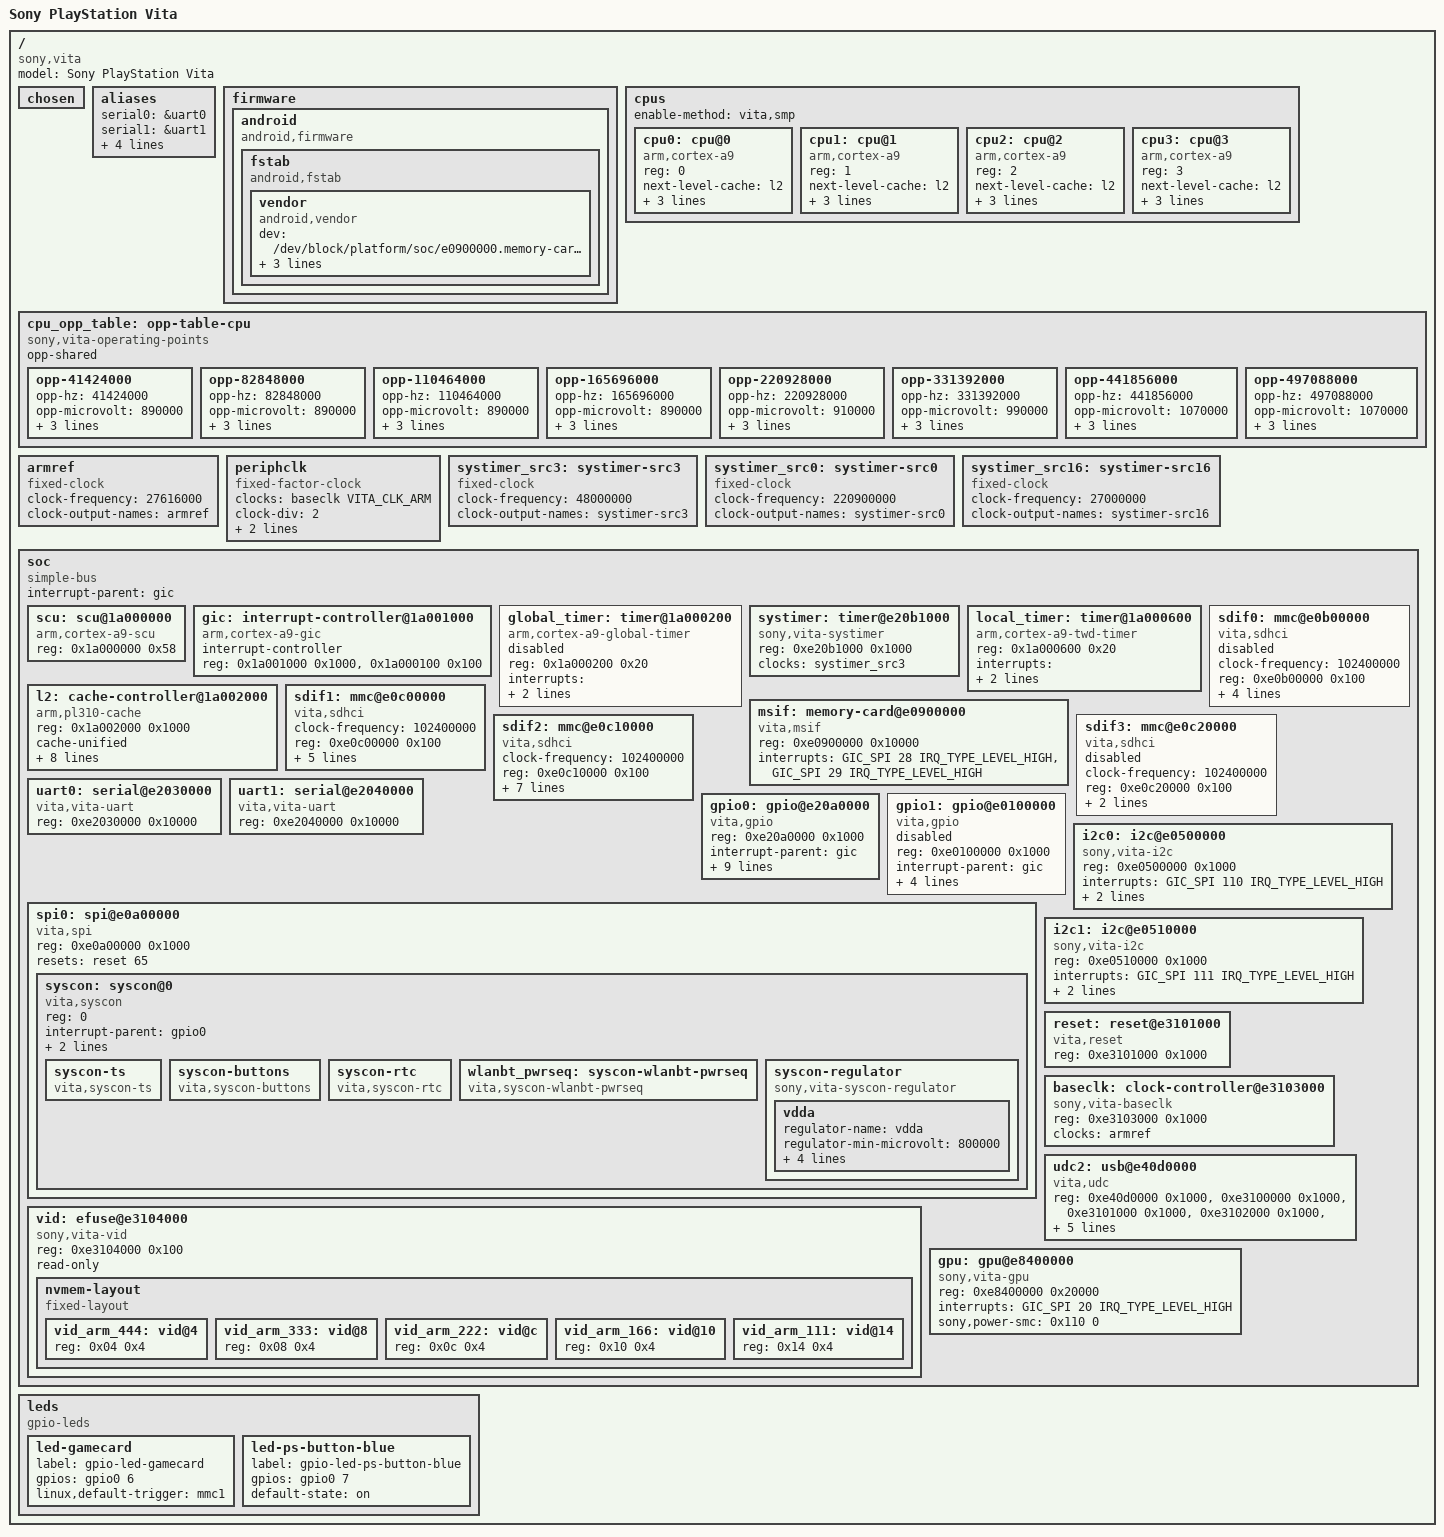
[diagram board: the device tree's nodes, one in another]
// SPDX-License-Identifier: GPL-2.0
/*
 * Base Device Tree Source for the PlayStation Vita (CXD5315GG SoC)
 *
 * Sources of the hardware values:
 *  [HW]   measured on a DevKit by a bare-metal test payload;
 *  [WIKI] the wiki.henkaku.xyz pages;
 *  [RE]   the Vita OS 3.65 modules, reverse engineered.
 * Interrupt numbers in the wiki's SceKernelIntrMgr table are GIC interrupt
 * IDs; GIC_SPI n below is ID - 32.
 */

#include <dt-bindings/clock/sony,vita-baseclk.h>
#include <dt-bindings/gpio/gpio.h>
#include <dt-bindings/interrupt-controller/arm-gic.h>
#include <dt-bindings/interrupt-controller/irq.h>

/ {
	model = "Sony PlayStation Vita";
	compatible = "sony,vita", "vita,vita";

	#address-cells = <1>;
	#size-cells = <1>;

	chosen {
		#address-cells = <1>;
		#size-cells = <1>;
		ranges;
	};

	aliases {
		serial0 = &uart0;
		serial1 = &uart1;
		/* Fixed MMC numbering: mmc0 is always the eMMC, mmc1 the game card slot */
		mmc0 = &sdif0;
		mmc1 = &sdif1;
		mmc2 = &sdif2;
		mmc3 = &sdif3;
	};

	/*
	 * Android's first-stage mount. The boot loader maps ux0:data/android/emmc.img
	 * to the GPT disk vitaemmc (see msif below); system is the root file
	 * system (root=PARTLABEL=system), vendor is mounted from here before
	 * SELinux loads its policy.
	 */
	firmware {
		android {
			compatible = "android,firmware";

			fstab {
				compatible = "android,fstab";

				vendor {
					compatible = "android,vendor";
					dev = "/dev/block/platform/soc/e0900000.memory-card/by-name/vendor";
					type = "ext4";
					mnt_flags = "ro,barrier=1";
					fsmgr_flags = "wait";
				};
			};
		};
	};

	cpus {
		#address-cells = <1>;
		#size-cells = <0>;
		/* Secondaries are parked by the loader at 0x1F007F00 + 4 * cpu */
		enable-method = "vita,smp";

		/* 4x Cortex-A9 r2p10 (MIDR 0x412FC09A) [WIKI CPU] */
		cpu0: cpu@0 {
			device_type = "cpu";
			compatible = "arm,cortex-a9";
			reg = <0>;
			next-level-cache = <&l2>;
			clocks = <&baseclk VITA_CLK_ARM>;
			cpu-supply = <&vdda>;
			operating-points-v2 = <&cpu_opp_table>;
		};

		cpu1: cpu@1 {
			device_type = "cpu";
			compatible = "arm,cortex-a9";
			reg = <1>;
			next-level-cache = <&l2>;
			clocks = <&baseclk VITA_CLK_ARM>;
			cpu-supply = <&vdda>;
			operating-points-v2 = <&cpu_opp_table>;
		};

		cpu2: cpu@2 {
			device_type = "cpu";
			compatible = "arm,cortex-a9";
			reg = <2>;
			next-level-cache = <&l2>;
			clocks = <&baseclk VITA_CLK_ARM>;
			cpu-supply = <&vdda>;
			operating-points-v2 = <&cpu_opp_table>;
		};

		cpu3: cpu@3 {
			device_type = "cpu";
			compatible = "arm,cortex-a9";
			reg = <3>;
			next-level-cache = <&l2>;
			clocks = <&baseclk VITA_CLK_ARM>;
			cpu-supply = <&vdda>;
			operating-points-v2 = <&cpu_opp_table>;
		};
	};

	/*
	 * The ARM clock's operating points: the selectors whose L2 clock is the
	 * core clock, the ones ScePower uses and the boot loader's 500 MHz
	 * (drivers/clk/clk-vita.c), at 27.616 MHz times 1.5, 3, 4, 6, 8, 12, 16
	 * and 18. Each OPP names the ScePervasiveVid cell ScePower takes for
	 * its level (power.skprx 3.65 0x810098e0), 500 MHz the one for 444 MHz
	 * as the boot loader does; the driver sets the voltage from it. The
	 * opp-microvolt values are those of the wiki's example chip.
	 * clock-latency-ns covers the Syscon voltage command, an estimate.
	 */
	cpu_opp_table: opp-table-cpu {
		compatible = "sony,vita-operating-points";
		opp-shared;

		opp-41424000 {
			opp-hz = /bits/ 64 <41424000>;
			opp-microvolt = <890000>;
			clock-latency-ns = <1000000>;
			nvmem-cells = <&vid_arm_111>;
			nvmem-cell-names = "vid";
		};

		opp-82848000 {
			opp-hz = /bits/ 64 <82848000>;
			opp-microvolt = <890000>;
			clock-latency-ns = <1000000>;
			nvmem-cells = <&vid_arm_111>;
			nvmem-cell-names = "vid";
		};

		opp-110464000 {
			opp-hz = /bits/ 64 <110464000>;
			opp-microvolt = <890000>;
			clock-latency-ns = <1000000>;
			nvmem-cells = <&vid_arm_111>;
			nvmem-cell-names = "vid";
		};

		opp-165696000 {
			opp-hz = /bits/ 64 <165696000>;
			opp-microvolt = <890000>;
			clock-latency-ns = <1000000>;
			nvmem-cells = <&vid_arm_166>;
			nvmem-cell-names = "vid";
		};

		opp-220928000 {
			opp-hz = /bits/ 64 <220928000>;
			opp-microvolt = <910000>;
			clock-latency-ns = <1000000>;
			nvmem-cells = <&vid_arm_222>;
			nvmem-cell-names = "vid";
		};

		opp-331392000 {
			opp-hz = /bits/ 64 <331392000>;
			opp-microvolt = <990000>;
			clock-latency-ns = <1000000>;
			nvmem-cells = <&vid_arm_333>;
			nvmem-cell-names = "vid";
		};

		opp-441856000 {
			opp-hz = /bits/ 64 <441856000>;
			opp-microvolt = <1070000>;
			clock-latency-ns = <1000000>;
			nvmem-cells = <&vid_arm_444>;
			nvmem-cell-names = "vid";
		};

		opp-497088000 {
			opp-hz = /bits/ 64 <497088000>;
			opp-microvolt = <1070000>;
			clock-latency-ns = <1000000>;
			nvmem-cells = <&vid_arm_444>;
			nvmem-cell-names = "vid";
		};
	};

	/* The memory node is per model: 512 MiB retail, 1 GiB DevKit */

	/*
	 * Reference of the ARM clock. The wiki gives 27.777 MHz [WIKI
	 * Pervasive]; PERIPHCLK measured 165.7 MHz at selector 7 (x12) and the
	 * cycle counter 497 MHz at selector 15 (x18) [HW], so 27.616 MHz, which
	 * puts every operating point on a whole kHz.
	 */
	armref: armref {
		compatible = "fixed-clock";
		#clock-cells = <0>;
		clock-frequency = <27616000>;
		clock-output-names = "armref";
	};

	/*
	 * PERIPHCLK of the MPCore private block, which clocks the global timer
	 * and the private (TWD) timers: the ARM clock divided by two. The TWD
	 * follows its rate changes. (The boot loader still sets a
	 * clock-frequency here, which a fixed-factor clock ignores.)
	 */
	periphclk: periphclk {
		compatible = "fixed-factor-clock";
		#clock-cells = <0>;
		clocks = <&baseclk VITA_CLK_ARM>;
		clock-div = <2>;
		clock-mult = <1>;
		clock-output-names = "periphclk";
	};

	/*
	 * System timer (SceSystimer, 0xE20B0000) source clocks: source 0
	 * ~220.9 MHz and source 16 = 27 MHz (the display driver's clock)
	 * [HW]; source 3 48 MHz, which the Vita OS divides by 48 for its 1 MHz
	 * system time [RE SceSystimer].
	 */
	systimer_src3: systimer-src3 {
		compatible = "fixed-clock";
		#clock-cells = <0>;
		clock-frequency = <48000000>;
		clock-output-names = "systimer-src3";
	};

	systimer_src0: systimer-src0 {
		compatible = "fixed-clock";
		#clock-cells = <0>;
		clock-frequency = <220900000>;
		clock-output-names = "systimer-src0";
	};

	systimer_src16: systimer-src16 {
		compatible = "fixed-clock";
		#clock-cells = <0>;
		clock-frequency = <27000000>;
		clock-output-names = "systimer-src16";
	};

	soc {
		#address-cells = <1>;
		#size-cells = <1>;
		compatible = "simple-bus";
		interrupt-parent = <&gic>;
		ranges;

		/*
		 * Cortex-A9 MPCore private region at 0x1A000000 [WIKI].
		 * SCU CTRL reads 0x61 (enabled, SCU + IC standby) and CONFIG
		 * 0x55F3 (4 CPUs, all in SMP mode, 32 KiB L1 tag RAMs) [HW].
		 */
		scu: scu@1a000000 {
			compatible = "arm,cortex-a9-scu";
			reg = <0x1a000000 0x58>;
		};

		/*
		 * GIC: GICD_TYPER 0xFC67 (256 interrupt IDs, 4 CPUs, security
		 * extensions, 31 lockable SPIs), GICD_IIDR 0x0102043B,
		 * GICC_IIDR 0x3901243B [HW].
		 * The CPU interface is 0x100 bytes at +0x100 (xerpi's 0x1000
		 * covered the global and private timers too).
		 */
		gic: interrupt-controller@1a001000 {
			compatible = "arm,cortex-a9-gic";
			#interrupt-cells = <3>;
			#address-cells = <0>;
			interrupt-controller;
			reg = <0x1a001000 0x1000>,
			      <0x1a000100 0x100>;
		};

		/*
		 * The global timer counts on the DevKit from the non-secure side
		 * (the probe measured its rate) [HW]. xerpi had it disabled and
		 * ran without a clocksource.
		 * TODO: confirm SCU SNSAC lets the non-secure side write its
		 * control register on retail units too.
		 */
		global_timer: timer@1a000200 {
			compatible = "arm,cortex-a9-global-timer";
			/*
			 * Counts PERIPHCLK, which follows the ARM clock; its
			 * prescaler cannot keep one rate across 333, 444 and
			 * 500 MHz. The system timer below is the clocksource.
			 */
			status = "disabled";
			reg = <0x1a000200 0x20>;
			interrupts = <GIC_PPI 11 (GIC_CPU_MASK_SIMPLE(4) | IRQ_TYPE_EDGE_RISING)>;
			clocks = <&periphclk>;
		};

		/*
		 * Long-range system timer 0, free once the Vita OS is gone (units
		 * 0-4 are SceSystimer's, 5 is the Vita OS system time) [RE
		 * SceSystimer]: the clocksource, sched_clock and delay timer.
		 */
		systimer: timer@e20b1000 {
			compatible = "sony,vita-systimer";
			reg = <0xe20b1000 0x1000>;
			clocks = <&systimer_src3>;
		};

		local_timer: timer@1a000600 {
			compatible = "arm,cortex-a9-twd-timer";
			reg = <0x1a000600 0x20>;
			interrupts = <GIC_PPI 13 (GIC_CPU_MASK_SIMPLE(4) | IRQ_TYPE_EDGE_RISING)>;
			clocks = <&periphclk>;
		};

		/*
		 * PL310 r3p1: Cache ID 0x410000C7, Cache Type 0x1E440440
		 * (16 ways of 128 KiB, 32-byte lines: 2 MiB) [WIKI Caches, HW].
		 * NSKBL programs AUX 0x60090001, tag latency 0 (1 cycle),
		 * data latency 0x131 (read 4, write 2, setup 2 cycles) and
		 * prefetch 0x20000000 (instruction prefetch) [WIKI Caches].
		 * The L2 is already enabled when Linux starts, so these are
		 * only used if a loader ever hands over with it disabled.
		 */
		l2: cache-controller@1a002000 {
			compatible = "arm,pl310-cache";
			reg = <0x1a002000 0x1000>;
			cache-unified;
			cache-level = <2>;
			cache-size = <0x200000>;
			cache-sets = <4096>;
			cache-line-size = <32>;
			arm,tag-latency = <1 1 1>;
			arm,data-latency = <4 2 2>;
			prefetch-instr = <1>;
			prefetch-data = <0>;
		};

		/* SceMsif: Memory Card (ux0) [WIKI Memory_Mapping] */
		msif: memory-card@e0900000 {
			compatible = "vita,msif";
			reg = <0xe0900000 0x10000>;
			/* SceMsifIns (ID 60), SceMsifSmshc (ID 61) [WIKI SceKernelIntrMgr] */
			interrupts = <GIC_SPI 28 IRQ_TYPE_LEVEL_HIGH>,
				     <GIC_SPI 29 IRQ_TYPE_LEVEL_HIGH>;
			interrupt-names = "insert", "smshc";
			/*
			 * Deliberately no "resets": the card must stay powered and
			 * authenticated by the boot loader (commands 0x48-0x4B), and a
			 * reset of the controller or the card would undo that.
			 *
			 * The boot loader adds one child per ux0 file it maps, so
			 * Linux reaches nothing else on the card:
			 *	emmc { label = "emmc"; vita,extents = <...>; };
			 *	sdcard { label = "sdcard"; vita,extents = <...>; };
			 */
			status = "okay";
		};

		/*
		 * SceSdif0-3: SDHCI 2.0 hosts (Host Controller Version 0x8901,
		 * vendor 0x89) with the register block mirrored every 0x100
		 * [WIKI SDIF_Registers]. Pervasive reset bits at
		 * +0xA0..+0xAC [WIKI Pervasive]: indices 40..43.
		 *
		 * clock-frequency is the SD base clock. It is not documented;
		 * 102.4 MHz is an upper bound. libbaremetal identifies cards with
		 * SDHCI divider 128 (base/256), which must be <= 400 kHz. Assuming
		 * the upper bound keeps every real SD clock at or below the
		 * requested one. TODO: measure the base clock.
		 */
		sdif0: mmc@e0b00000 {
			compatible = "vita,sdhci";
			clock-frequency = <102400000>;
			reg = <0xe0b00000 0x100>;
			interrupts = <GIC_SPI 188 IRQ_TYPE_LEVEL_HIGH>;	/* ID 220 */
			resets = <&reset 40>;
			bus-width = <8>;
			non-removable;
			/*
			 * The eMMC holds the Vita OS and is block-encrypted by the
			 * SoC; leave it alone.
			 */
			status = "disabled";
		};

		/* Game card slot: an SD2Vita adapter makes it a microSD slot */
		sdif1: mmc@e0c00000 {
			compatible = "vita,sdhci";
			clock-frequency = <102400000>;
			reg = <0xe0c00000 0x100>;
			interrupts = <GIC_SPI 189 IRQ_TYPE_LEVEL_HIGH>;	/* ID 221 */
			resets = <&reset 41>;
			bus-width = <4>;
			cap-sd-highspeed;
			/* TODO: 1.8 V signalling goes through ScePervasiveMisc +0x124 */
			no-1-8-v;
			/* TODO: slot power is a Syscon command; the loader leaves it on */
			status = "okay";
		};

		/*
		 * WLAN/BT: "Robin", a Marvell 88W8787 SDIO card with WLAN
		 * function 1 (02df:9119, mwifiex_sdio) and Bluetooth function 2
		 * (02df:911a, btmrvl_sdio) [WIKI Robin, Components].
		 * Its I/O runs at 1.8 V (SceSdif selects it in ScePervasiveMisc
		 * +0x124 bit 2; the boot loader does the same), and the Syscon
		 * powers and resets it (wlanbt_pwrseq).
		 */
		sdif2: mmc@e0c10000 {
			compatible = "vita,sdhci";
			clock-frequency = <102400000>;
			reg = <0xe0c10000 0x100>;
			interrupts = <GIC_SPI 190 IRQ_TYPE_LEVEL_HIGH>;	/* ID 222 */
			resets = <&reset 42>;
			bus-width = <4>;
			non-removable;
			no-sd;
			no-mmc;
			mmc-pwrseq = <&wlanbt_pwrseq>;
			status = "okay";
		};

		sdif3: mmc@e0c20000 {
			compatible = "vita,sdhci";
			clock-frequency = <102400000>;
			reg = <0xe0c20000 0x100>;
			/* ID 223 (assumed): not in the wiki's interrupt table */
			interrupts = <GIC_SPI 191 IRQ_TYPE_LEVEL_HIGH>;
			resets = <&reset 43>;
			status = "disabled";
		};

		/*
		 * UART0: debug console. It has no registered interrupt in the OS
		 * (only UART1 ID 225 and UART6 ID 230 do [WIKI SceKernelIntrMgr]),
		 * so the driver polls.
		 */
		uart0: serial@e2030000 {
			compatible = "vita,vita-uart";
			reg = <0xe2030000 0x10000>;
		};

		/*
		 * UART1: on a DevKit, the line to the CP board, whose dfcpm opens
		 * it as its ttyS1 (115200 8N1) and relays the text to the PC over
		 * the mini-USB port as DECI4p console output (protocol
		 * 0x80030081).  The bootloader clocks and initialises it; polled
		 * like UART0.
		 */
		uart1: serial@e2040000 {
			compatible = "vita,vita-uart";
			reg = <0xe2040000 0x10000>;
		};

		/* GPIO0: port mode register 1 = output [WIKI GPIO_Registers] */
		gpio0: gpio@e20a0000 {
			compatible = "vita,gpio";
			#address-cells = <1>;
			#size-cells = <1>;
			reg = <0xe20a0000 0x1000>;

			interrupt-parent = <&gic>;
			/* SceGpio0Gate0-4, IDs 248-252 [WIKI SceKernelIntrMgr] */
			interrupts = <GIC_SPI 216 IRQ_TYPE_LEVEL_HIGH>,
				     <GIC_SPI 217 IRQ_TYPE_LEVEL_HIGH>,
				     <GIC_SPI 218 IRQ_TYPE_LEVEL_HIGH>,
				     <GIC_SPI 219 IRQ_TYPE_LEVEL_HIGH>,
				     <GIC_SPI 220 IRQ_TYPE_LEVEL_HIGH>;

			gpio-controller;
			#gpio-cells = <2>;
			ngpios = <32>;

			interrupt-controller;
			#interrupt-cells = <2>;

			/* ScePervasiveReset +0x100 */
			resets = <&reset 64>;
			reset-names = "gpio0_reset";
		};

		/*
		 * GPIO1 (0xE0100000): gate 0/1 interrupts are IDs 253/254, gates
		 * 2-4 are listed as IDs 49-51 [WIKI SceKernelIntrMgr]. Its
		 * Pervasive reset/gate bit is not documented.
		 * TODO: find the reset bit before enabling.
		 */
		gpio1: gpio@e0100000 {
			compatible = "vita,gpio";
			reg = <0xe0100000 0x1000>;
			interrupt-parent = <&gic>;
			interrupts = <GIC_SPI 221 IRQ_TYPE_LEVEL_HIGH>;
			gpio-controller;
			#gpio-cells = <2>;
			ngpios = <32>;
			interrupt-controller;
			#interrupt-cells = <2>;
			status = "disabled";
		};

		/* SceSpi0 (Syscon) [WIKI SPI_Registers]; ScePervasiveReset +0x104 */
		spi0: spi@e0a00000 {
			compatible = "vita,spi";
			reg = <0xe0a00000 0x1000>;
			#address-cells = <1>;
			#size-cells = <0>;

			resets = <&reset 65>;
			reset-names = "spi0_reset";

			syscon: syscon@0 {
				compatible = "vita,syscon";
				reg = <0>;

				/* GPIO0 port 4: Syscon (input); port 3: Syscon (output) [WIKI GPIO_Registers] */
				interrupt-parent = <&gpio0>;
				interrupts = <4 IRQ_TYPE_EDGE_FALLING>;

				tx-gpios = <&gpio0 3 GPIO_ACTIVE_LOW>;

				syscon-ts {
					compatible = "vita,syscon-ts";
				};

				syscon-buttons {
					compatible = "vita,syscon-buttons";
				};

				syscon-rtc {
					compatible = "vita,syscon-rtc";
				};

				/*
				 * WLAN/BT module supply (Syscon command 0x88A) and
				 * reset (command 0x88F, device 0x10), as SceWlanBt
				 * drives them [WIKI SceSyscon, wlanbt.skprx
				 * 0x81000168]. The boot loader enables the module's
				 * 27 MHz clock (SceClockgen register 1 bit 7).
				 */
				wlanbt_pwrseq: syscon-wlanbt-pwrseq {
					compatible = "vita,syscon-wlanbt-pwrseq";
				};

				/*
				 * Core rails, Syscon command 0x088E. VDDA feeds
				 * the ARM cores and L2; the limits bound the
				 * voltages the chip's IDs can ask for. The boot
				 * loader leaves VDDA at its 444 MHz voltage
				 * (clocks_max(), ScePervasiveVid +0x04).
				 */
				syscon-regulator {
					compatible = "sony,vita-syscon-regulator";

					vdda: vdda {
						regulator-name = "vdda";
						regulator-min-microvolt = <800000>;
						regulator-max-microvolt = <1200000>;
						regulator-always-on;
						nvmem-cells = <&vid_arm_444>;
						nvmem-cell-names = "boot-vid";
					};
				};
			};
		};

		/*
		 * SceI2c0Reg/SceI2c1Reg [WIKI I2C_Registers]: IDs 142/143 [RE
		 * SceLowio], ScePervasiveReset +0x110 + 4n. Speed mode 5
		 * is what SceLowio sets on Hardware Info below 0x800000.
		 * Bus 0: codec 0x1a, clock generator 0x69, back camera 0x3a;
		 * bus 1: front camera 0x3a, HDMI bridge [RE].
		 */
		i2c0: i2c@e0500000 {
			compatible = "sony,vita-i2c";
			reg = <0xe0500000 0x1000>;
			interrupts = <GIC_SPI 110 IRQ_TYPE_LEVEL_HIGH>;
			resets = <&reset 68>;
			sony,speed-mode = <5>;
			#address-cells = <1>;
			#size-cells = <0>;
		};

		i2c1: i2c@e0510000 {
			compatible = "sony,vita-i2c";
			reg = <0xe0510000 0x1000>;
			interrupts = <GIC_SPI 111 IRQ_TYPE_LEVEL_HIGH>;
			resets = <&reset 69>;
			sony,speed-mode = <5>;
			#address-cells = <1>;
			#size-cells = <0>;
		};

		/* ScePervasiveReset: one bit per device, set = held in reset [WIKI Pervasive] */
		reset: reset@e3101000 {
			compatible = "vita,reset";
			#reset-cells = <1>;
			reg = <0xe3101000 0x1000>;
		};

		/* ScePervasiveBaseClk: clock multipliers and dividers [WIKI Pervasive] */
		baseclk: clock-controller@e3103000 {
			compatible = "sony,vita-baseclk";
			reg = <0xe3103000 0x1000>;
			clocks = <&armref>;
			clock-names = "ref";
			#clock-cells = <1>;
		};

		/*
		 * ScePervasiveVid: the chip's voltage IDs; the VDDA words
		 * by the ARM clock level ScePower takes them for [WIKI
		 * Pervasive, power.skprx 3.65 0x8100399c].
		 */
		vid: efuse@e3104000 {
			compatible = "sony,vita-vid";
			reg = <0xe3104000 0x100>;
			read-only;

			nvmem-layout {
				compatible = "fixed-layout";
				#address-cells = <1>;
				#size-cells = <1>;

				vid_arm_444: vid@4 {
					reg = <0x04 0x4>;
				};

				vid_arm_333: vid@8 {
					reg = <0x08 0x4>;
				};

				vid_arm_222: vid@c {
					reg = <0x0c 0x4>;
				};

				vid_arm_166: vid@10 {
					reg = <0x10 0x4>;
				};

				vid_arm_111: vid@14 {
					reg = <0x14 0x4>;
				};
			};
		};

		/*
		 * USB device controller of the multi-connector (micro-USB on the
		 * PCH-2000), udcd's bus 2: Toshiba UDC2 core at +0x200, Kermit DMA
		 * blocks at +0x400 [RE udcd.skprx 3.65]. Its PHY mode, power,
		 * reset and gate words are in Pervasive; PHY ready and VBUS in
		 * Pervasive2. IDs 155/156 controller/DMA, 171 VBUS
		 * [udcd.skprx 0x810082a0]. VBUS comes from Pervasive2 +0xF50 bit 2,
		 * on the PCH-1000 together with GPIO0 port 5 (vita1000.dts).
		 */
		udc2: usb@e40d0000 {
			compatible = "vita,udc";
			reg = <0xe40d0000 0x1000>,
			      <0xe3100000 0x1000>,
			      <0xe3101000 0x1000>,
			      <0xe3102000 0x1000>,
			      <0xe3110000 0x1000>;
			reg-names = "udc", "misc", "reset", "gate", "pervasive2";
			interrupts = <GIC_SPI 123 IRQ_TYPE_LEVEL_HIGH>,	/* ID 155 */
				     <GIC_SPI 124 IRQ_TYPE_LEVEL_HIGH>,	/* ID 156 */
				     <GIC_SPI 139 IRQ_TYPE_LEVEL_HIGH>;	/* ID 171 */
			interrupt-names = "udc", "dma", "vbus";
			vita,usb-bus = <2>;
		};

		/*
		 * PowerVR SGX543MP4+: CORE_ID 0x01174403, CORE_REVISION 0x00020106
		 * [HW]. Power-up needs SMC 0x110 and the
		 * SGXStart sequence before any register access; SceGpuLisr is ID 52
		 * [WIKI SceKernelIntrMgr]. There is no open SGX543 driver, so Android
		 * renders in software.
		 */
		/*
		 * Bank 0 at +0, the multi-core master at +0x4000 and core n at
		 * +0x8000 + n * 0x4000: 0x20000 bytes.  The power domain is
		 * switched by the secure monitor's SMC 0x110 on bus 0.
		 */
		gpu: gpu@e8400000 {
			compatible = "sony,vita-gpu", "img,powervr-sgx543";
			reg = <0xe8400000 0x20000>;
			interrupts = <GIC_SPI 20 IRQ_TYPE_LEVEL_HIGH>;
			sony,power-smc = <0x110 0>;
			status = "okay";
		};
	};

	leds {
		compatible = "gpio-leds";

		/* GPIO0 ports 6/7 [WIKI GPIO_Registers] */
		led-gamecard {
			label = "gpio-led-gamecard";
			gpios = <&gpio0 6 GPIO_ACTIVE_HIGH>;
			linux,default-trigger = "mmc1";	/* the game card slot */
		};

		led-ps-button-blue {
			label = "gpio-led-ps-button-blue";
			gpios = <&gpio0 7 GPIO_ACTIVE_HIGH>;
			default-state = "on";
		};
	};
};
